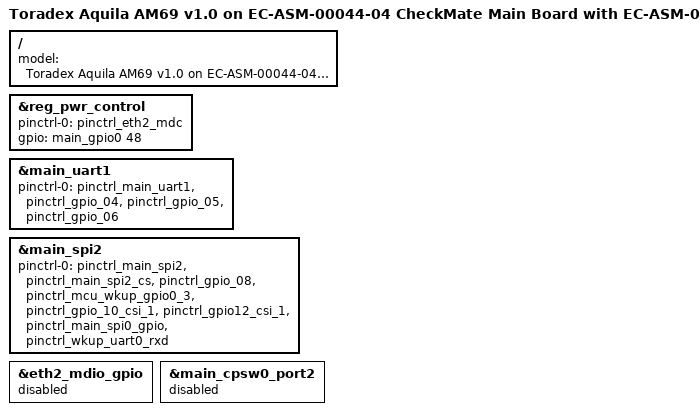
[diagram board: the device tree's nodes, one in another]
// SPDX-License-Identifier: GPL-2.0-or-later OR MIT
/*
 * Copyright (C) 2025 Toradex
 * Copyright 2025 Refeyn
 *
 * Device tree for EC-ASM-00044-04 CheckMate Main Board with EC-ASM-00048-02 CheckMate Screen Adaptor
 */

#include "k3-am69-aquila-v1.1-ec-asm-00044-04-ec-asm-00048-02.dts"
#include "k3-am69-aquila-v1.0.dtsi"

/ {
	model = "Toradex Aquila AM69 v1.0 on EC-ASM-00044-04 CheckMate Main Board with EC-ASM-00048-02 CheckMate Screen Adaptor";
};

&reg_pwr_control {
	pinctrl-0 = <&pinctrl_eth2_mdc>;
	gpio = <&main_gpio0 48 GPIO_ACTIVE_HIGH>;
};

/* Aquila UART_1 (SoM v1.0) */
&main_uart1 {
	status = "okay";
	pinctrl-0 =
		// UART
		<&pinctrl_main_uart1>,
		// GPIOs
		<&pinctrl_gpio_04>, // RTCPU_RESET
		<&pinctrl_gpio_05>, // RTCPU_MODE_0
		<&pinctrl_gpio_06>; // RTCPU_MODE_1
};

/* Aquila SPI_1 */
&main_spi2 {
	status = "okay";
	pinctrl-0 =
		// SPI and CS pins
		<&pinctrl_main_spi2>,
		<&pinctrl_main_spi2_cs>, // CS1 (HW 1) and CS2 (HW 0)
		// Shutter pins
		<&pinctrl_gpio_08>, // SHUTTER_EN
		<&pinctrl_mcu_wkup_gpio0_3>, // SHUTTER_ACTIVE
		// Interlock pins
		<&pinctrl_gpio_10_csi_1>, // INTERLOCK_STATUS_0
		<&pinctrl_gpio12_csi_1>, // INTERLOCK_STATUS_1
		// Laser safety pins
		<&pinctrl_main_spi0_gpio>,
		// Laser driver board ID
		<&pinctrl_wkup_uart0_rxd>;
};

&eth2_mdio_gpio {
	status = "disabled";
};

&main_cpsw0_port2 {
	status = "disabled";
};
